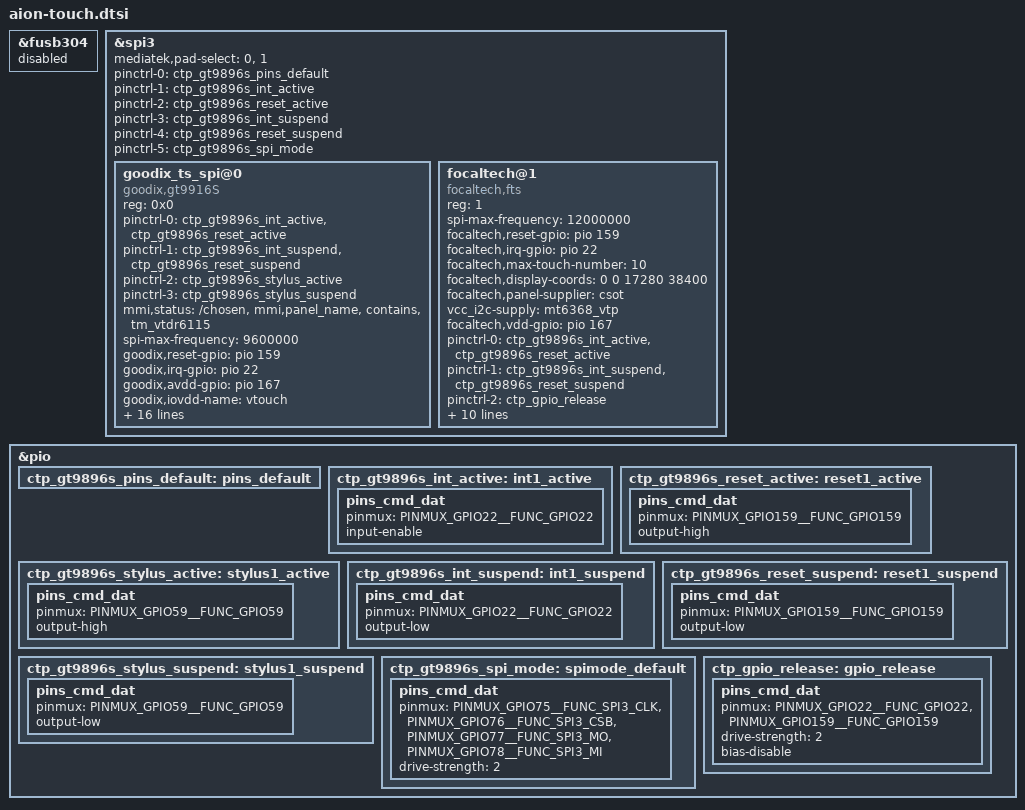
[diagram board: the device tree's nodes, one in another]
// SPDX-License-Identifier: (GPL-2.0 OR MIT)
/*
 * Copyright (C) 2020 MediaTek Inc.
 */

/* TOUCH start */

&fusb304 {
	status = "disabled";
};

&spi3 {
	status = "okay";
	#address-cells = <1>;
	#size-cells = <0>;
	mediatek,pad-select = <0>, <1>;
	pinctrl-names = "default", "gt9896s_int_active",
		"gt9896s_reset_active", "gt9896s_int_suspend",
		"gt9896s_reset_suspend", "gt9896s_spi_mode";
	pinctrl-0 = <&ctp_gt9896s_pins_default>;
	pinctrl-1 = <&ctp_gt9896s_int_active>;
	pinctrl-2 = <&ctp_gt9896s_reset_active>;
	pinctrl-3 = <&ctp_gt9896s_int_suspend>;
	pinctrl-4 = <&ctp_gt9896s_reset_suspend>;
	pinctrl-5 = <&ctp_gt9896s_spi_mode>;

	goodix_ts_spi@0 {
		status = "ok";
		compatible = "goodix,gt9916S";
		reg = <0x0>;
		pinctrl-names = "pmx_ts_active", "pmx_ts_suspend", "stylus_clk_active", "stylus_clk_suspend";
		pinctrl-0 = <&ctp_gt9896s_int_active &ctp_gt9896s_reset_active>;
		pinctrl-1 = <&ctp_gt9896s_int_suspend &ctp_gt9896s_reset_suspend>;
		pinctrl-2 = <&ctp_gt9896s_stylus_active>;
		pinctrl-3 = <&ctp_gt9896s_stylus_suspend>;
		mmi,status = "/chosen","mmi,panel_name","contains","tm_vtdr6115";
		spi-max-frequency = <9600000>;  /* 4800000,9600000,15000000,19200000 */
		goodix,reset-gpio = <&pio 159 0x0>;
		goodix,irq-gpio = <&pio 22 0x2002>;
		goodix,avdd-gpio = <&pio 167 0x0>;
		goodix,iovdd-name = "vtouch";
		vtouch-supply = <&mt6368_vtp>;
		goodix,irq-flags = <0x2002>; /* 1:trigger rising, 2:trigger falling;*/
		goodix,panel-max-id = <10>;
		goodix,panel-max-x = <17280>;
		goodix,panel-max-y = <38400>;
		goodix,panel-max-w = <256>;
		goodix,panel-max-p = <256>;
		goodix,edge-ctrl;
		goodix,sample-ctrl;
		goodix,interpolation-ctrl;
		goodix,stowed-mode-ctrl;
		mmi,enable-gestures;
		mmi,power-off-suspend;
		mmi,usb-charger-detection;
		mmi,supported_gesture_type = <0x07>;
		mtk-charger = <&mt6375_chg>;
	};

	focaltech@1 {
		status = "ok";
		compatible = "focaltech,fts";
		reg = <1>;
		spi-max-frequency = <12000000>;

		focaltech,reset-gpio = <&pio 159 0x0>;
		focaltech,irq-gpio = <&pio 22 0x2800>;
		focaltech,max-touch-number = <10>;
		focaltech,display-coords =  <0 0 17280 38400>;
		focaltech,panel-supplier = "csot";
		vcc_i2c-supply = <&mt6368_vtp>;
		focaltech,vdd-gpio = <&pio 167 0x0>;

		pinctrl-names = "pmx_ts_active","pmx_ts_suspend","pmx_ts_release";
		pinctrl-0 = <&ctp_gt9896s_int_active &ctp_gt9896s_reset_active>;
		pinctrl-1 = <&ctp_gt9896s_int_suspend &ctp_gt9896s_reset_suspend>;
		pinctrl-2 = <&ctp_gpio_release>;
		mmi,status = "/chosen","mmi,panel_name","contains","csot_vtdr6115";
		focaltech,edge-ctrl;
		focaltech,sample-ctrl;
		focaltech,interpolation-ctrl;
		focaltech,stowed-mode-ctrl;
		mmi,enable-gestures;
		mmi,supported_gesture_type = <0x07>;
		mmi,usb-charger-detection;
		mtk-charger = <&mt6375_chg>;
    };
};

&pio {
	ctp_gt9896s_pins_default: pins_default {
	};
	ctp_gt9896s_int_active: int1_active {
		pins_cmd_dat {
			pinmux = <PINMUX_GPIO22__FUNC_GPIO22>;
			input-enable;
		};
	};
	ctp_gt9896s_reset_active: reset1_active {
		pins_cmd_dat {
			pinmux = <PINMUX_GPIO159__FUNC_GPIO159>;
			output-high;
		};
	};
	ctp_gt9896s_stylus_active: stylus1_active {
		pins_cmd_dat {
			pinmux = <PINMUX_GPIO59__FUNC_GPIO59>;
			output-high;
		};
	};
	ctp_gt9896s_int_suspend: int1_suspend {
		pins_cmd_dat {
			pinmux = <PINMUX_GPIO22__FUNC_GPIO22>;
			output-low;
		};
	};
	ctp_gt9896s_reset_suspend: reset1_suspend {
		pins_cmd_dat {
			pinmux = <PINMUX_GPIO159__FUNC_GPIO159>;
			output-low;
		};
	};
	ctp_gt9896s_stylus_suspend: stylus1_suspend {
		pins_cmd_dat {
			pinmux = <PINMUX_GPIO59__FUNC_GPIO59>;
			output-low;
		};
	};
	ctp_gt9896s_spi_mode: spimode_default {
		pins_cmd_dat {
			pinmux = <PINMUX_GPIO75__FUNC_SPI3_CLK>,
				<PINMUX_GPIO76__FUNC_SPI3_CSB>,
				<PINMUX_GPIO77__FUNC_SPI3_MO>,
				<PINMUX_GPIO78__FUNC_SPI3_MI>;
			drive-strength = <2>;
		};
	};
	ctp_gpio_release: gpio_release {
		pins_cmd_dat {
			pinmux = <PINMUX_GPIO22__FUNC_GPIO22>,
				<PINMUX_GPIO159__FUNC_GPIO159>;
			drive-strength = <2>;
			bias-disable;
		};
	};
};
/* TOUCH end */
